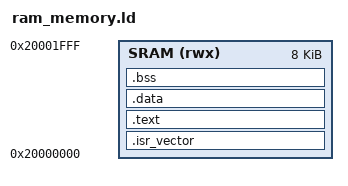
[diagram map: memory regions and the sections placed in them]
MEMORY {
    SRAM  (rwx) : ORIGIN = 0x20000000, LENGTH = 8K
}

SECTIONS {
    .isr_vector :
    {
        . = ALIGN(4);
        KEEP(*(.isr_vector))
        . = ALIGN(4);
    } > SRAM
 
    .text :
    {
        . = ALIGN(4);
        *(.text*)
        *(.rodata*)
        . = ALIGN(4);
        _etext = .;
    } > SRAM
 
    .data :
    {
        . = ALIGN(4);
        _sdata = .;
        *(.data*)
        . = ALIGN(4);
        _edata = .;
    } > SRAM AT > SRAM
 
    .bss :
    {
        . = ALIGN(4);
        _sbss = .;
        *(.bss*)
        *(COMMON)
        . = ALIGN(4);
        _ebss = .;
    } > SRAM

    _eram = ORIGIN(SRAM) + LENGTH(SRAM);
}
